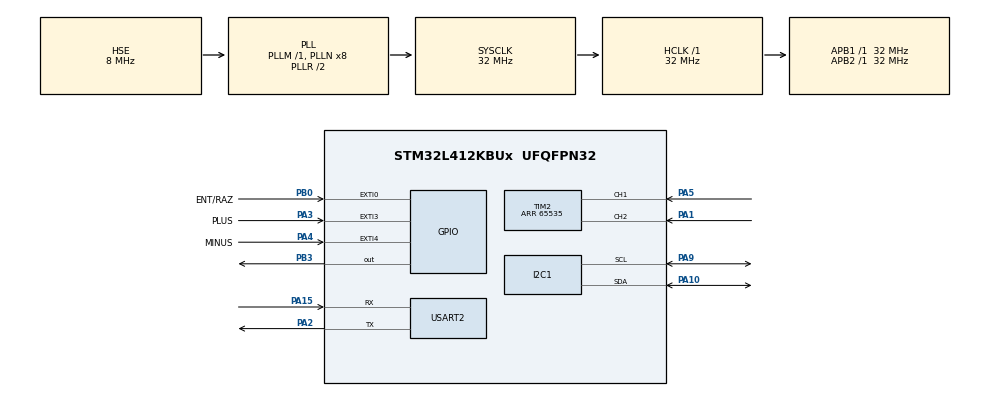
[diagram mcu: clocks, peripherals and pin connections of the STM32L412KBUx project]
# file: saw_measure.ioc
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Mcu.Family=STM32L4
Mcu.Name=STM32L412KBUx
Mcu.Package=UFQFPN32
NVIC.EXTI0_IRQn=true\:1\:0\:true\:false\:true\:true\:true
NVIC.EXTI3_IRQn=true\:3\:0\:true\:false\:true\:true\:true
NVIC.EXTI4_IRQn=true\:3\:0\:true\:false\:true\:true\:true
NVIC.PriorityGroup=NVIC_PRIORITYGROUP_4
NVIC.TIM2_IRQn=true\:0\:0\:false\:false\:true\:true\:true
PA0-CK_IN.Mode=HSE-External-Clock-Source-for-LittleOrca
PA0-CK_IN.Signal=RCC_CK_IN
PA1.Signal=S_TIM2_CH2
PA10.Mode=I2C
PA10.Signal=I2C1_SDA
PA13\ (JTMS/SWDIO).Mode=Serial_Wire
PA13\ (JTMS/SWDIO).Signal=SYS_JTMS-SWDIO
PA14\ (JTCK/SWCLK).Mode=Serial_Wire
PA14\ (JTCK/SWCLK).Signal=SYS_JTCK-SWCLK
PA15\ (JTDI).GPIO_ModeDefaultPP=GPIO_MODE_AF_PP
PA15\ (JTDI).GPIO_PuPd=GPIO_NOPULL
PA15\ (JTDI).GPIO_Speed=GPIO_SPEED_FREQ_VERY_HIGH
PA15\ (JTDI).Mode=Asynchronous
PA15\ (JTDI).Signal=USART2_RX
PA2.GPIO_ModeDefaultPP=GPIO_MODE_AF_PP
PA2.GPIO_PuPd=GPIO_NOPULL
PA2.GPIO_Speed=GPIO_SPEED_FREQ_VERY_HIGH
PA2.Mode=Asynchronous
PA2.Signal=USART2_TX
PA3.GPIO_Label=PLUS
PA3.GPIO_ModeDefaultEXTI=GPIO_MODE_IT_RISING
PA3.GPIO_PuPd=GPIO_NOPULL
PA3.Signal=GPXTI3
PA4.GPIO_Label=MINUS
PA4.GPIO_ModeDefaultEXTI=GPIO_MODE_IT_RISING
PA4.GPIO_PuPd=GPIO_NOPULL
PA4.Signal=GPXTI4
PA5.Signal=S_TIM2_CH1
PA9.Mode=I2C
PA9.Signal=I2C1_SCL
PB0.GPIO_Label=ENT/RAZ
PB0.GPIO_ModeDefaultEXTI=GPIO_MODE_IT_RISING
PB0.GPIO_PuPd=GPIO_NOPULL
PB0.Signal=GPXTI0
PB3\ (JTDO/TRACESWO).GPIO_ModeDefaultOutputPP=GPIO_MODE_OUTPUT_PP
PB3\ (JTDO/TRACESWO).GPIO_PuPd=GPIO_NOPULL
PB3\ (JTDO/TRACESWO).GPIO_Speed=GPIO_SPEED_FREQ_LOW
PB3\ (JTDO/TRACESWO).PinState=GPIO_PIN_RESET
PB3\ (JTDO/TRACESWO).Signal=GPIO_Output
PC14-OSC32_IN\ (PC14).Mode=LSE-External-Oscillator
PC14-OSC32_IN\ (PC14).Signal=RCC_OSC32_IN
PC15-OSC32_OUT\ (PC15).Mode=LSE-External-Oscillator
PC15-OSC32_OUT\ (PC15).Signal=RCC_OSC32_OUT
ProjectManager.HeapSize=0x200
ProjectManager.StackSize=0x400
ProjectManager.TargetToolchain=STM32CubeIDE
RCC.ADCFreq_Value=32000000
RCC.AHBFreq_Value=32000000
RCC.APB1Freq_Value=32000000
RCC.APB1TimFreq_Value=32000000
RCC.APB2Freq_Value=32000000
RCC.APB2TimFreq_Value=32000000
RCC.CortexFreq_Value=32000000
RCC.HCLKFreq_Value=32000000
RCC.HSE_VALUE=8000000
RCC.HSI48_VALUE=48000000
RCC.HSI_VALUE=16000000
RCC.MSI_VALUE=4000000
RCC.PLLSourceVirtual=RCC_PLLSOURCE_HSE
RCC.SYSCLKFreq_VALUE=32000000
RCC.SYSCLKSource=RCC_SYSCLKSOURCE_PLLCLK
RCC.USBFreq_Value=4000000
RCC.VCOOutputFreq_Value=64000000
SH.S_TIM2_CH1.0=TIM2_CH1,Encoder_Interface
SH.S_TIM2_CH2.0=TIM2_CH2,Encoder_Interface
TIM2.AutoReloadPreload=TIM_AUTORELOAD_PRELOAD_ENABLE
TIM2.EncoderMode=TIM_ENCODERMODE_TI12
TIM2.IC1Filter=10
TIM2.Period=65535
USART2.VirtualMode-Asynchronous=VM_ASYNC
board=NUCLEO-L412KB

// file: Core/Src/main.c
/* USER CODE BEGIN Header */
/**
  ******************************************************************************
  * @file           : main.c
  * @brief          : Main program body
  ******************************************************************************
  * @attention
  *
  * <h2><center>&copy; Copyright (c) 2020 STMicroelectronics.
  * All rights reserved.</center></h2>
  *
  * This software component is licensed by ST under BSD 3-Clause license,
  * the "License"; You may not use this file except in compliance with the
  * License. You may obtain a copy of the License at:
  *                        opensource.org/licenses/BSD-3-Clause
  *
  ******************************************************************************
  */
/* USER CODE END Header */
#include "main.h"

/* USER CODE BEGIN Includes */
#include "i2c-lcd.h"
#include "user_function.h"
#include <stdint.h>
/* USER CODE END Includes */

/* USER CODE BEGIN PD */

#define DEFAULT_TICKNESS 5U

uint8_t volatile valid_thickness = 0;
uint8_t volatile saw_thickness = DEFAULT_TICKNESS;
uint32_t volatile length = 0;

/* USER CODE END PD */

I2C_HandleTypeDef hi2c1;

TIM_HandleTypeDef htim2;

UART_HandleTypeDef huart2;

void SystemClock_Config(void);
static void MX_GPIO_Init(void);
static void MX_USART2_UART_Init(void);
static void MX_I2C1_Init(void);
static void MX_TIM2_Init(void);

int main(void)
{

  /* MCU Configuration--------------------------------------------------------*/

  /* Reset of all peripherals, Initializes the Flash interface and the Systick. */
  HAL_Init();

  /* USER CODE BEGIN Init */
  lcd_init();
  /* USER CODE END Init */

  /* Configure the system clock */
  SystemClock_Config();

  /* Initialize all configured peripherals */
  MX_GPIO_Init();
  MX_USART2_UART_Init();
  MX_I2C1_Init();
  MX_TIM2_Init();
  /* USER CODE BEGIN 2 */

  HAL_TIM_Encoder_Start_IT(&htim2, TIM_CHANNEL_ALL);

  /**
   * @brief First loop, ask user saw thickness as long as
   * 		user pressed ENTER/RAZ button
   */
  lcd_send_string("Ep lame :");
  display_saw_thickness(saw_thickness);

  while(!valid_thickness);

  display_measure(0 - saw_thickness);

  /* USER CODE END 2 */

  /* Infinite loop */
  while (1)
  {

  }
}

void SystemClock_Config(void)
{
  RCC_OscInitTypeDef RCC_OscInitStruct = {0};
  RCC_ClkInitTypeDef RCC_ClkInitStruct = {0};
  RCC_PeriphCLKInitTypeDef PeriphClkInit = {0};

  /** Configure the main internal regulator output voltage
  */
  if (HAL_PWREx_ControlVoltageScaling(PWR_REGULATOR_VOLTAGE_SCALE1) != HAL_OK)
  {
    Error_Handler();
  }
  /** Initializes the RCC Oscillators according to the specified parameters
  * in the RCC_OscInitTypeDef structure.
  */
  RCC_OscInitStruct.OscillatorType = RCC_OSCILLATORTYPE_HSE;
  RCC_OscInitStruct.HSEState = RCC_HSE_BYPASS;
  RCC_OscInitStruct.PLL.PLLState = RCC_PLL_ON;
  RCC_OscInitStruct.PLL.PLLSource = RCC_PLLSOURCE_HSE;
  RCC_OscInitStruct.PLL.PLLM = 1;
  RCC_OscInitStruct.PLL.PLLN = 8;
  RCC_OscInitStruct.PLL.PLLQ = RCC_PLLQ_DIV2;
  RCC_OscInitStruct.PLL.PLLR = RCC_PLLR_DIV2;
  if (HAL_RCC_OscConfig(&RCC_OscInitStruct) != HAL_OK)
  {
    Error_Handler();
  }
  /** Initializes the CPU, AHB and APB buses clocks
  */
  RCC_ClkInitStruct.ClockType = RCC_CLOCKTYPE_HCLK|RCC_CLOCKTYPE_SYSCLK
                              |RCC_CLOCKTYPE_PCLK1|RCC_CLOCKTYPE_PCLK2;
  RCC_ClkInitStruct.SYSCLKSource = RCC_SYSCLKSOURCE_PLLCLK;
  RCC_ClkInitStruct.AHBCLKDivider = RCC_SYSCLK_DIV1;
  RCC_ClkInitStruct.APB1CLKDivider = RCC_HCLK_DIV1;
  RCC_ClkInitStruct.APB2CLKDivider = RCC_HCLK_DIV1;

  if (HAL_RCC_ClockConfig(&RCC_ClkInitStruct, FLASH_LATENCY_1) != HAL_OK)
  {
    Error_Handler();
  }
  PeriphClkInit.PeriphClockSelection = RCC_PERIPHCLK_USART2|RCC_PERIPHCLK_I2C1;
  PeriphClkInit.Usart2ClockSelection = RCC_USART2CLKSOURCE_PCLK1;
  PeriphClkInit.I2c1ClockSelection = RCC_I2C1CLKSOURCE_PCLK1;
  if (HAL_RCCEx_PeriphCLKConfig(&PeriphClkInit) != HAL_OK)
  {
    Error_Handler();
  }
}

static void MX_I2C1_Init(void)
{

  hi2c1.Instance = I2C1;
  hi2c1.Init.Timing = 0x00000E14;
  hi2c1.Init.OwnAddress1 = 0;
  hi2c1.Init.AddressingMode = I2C_ADDRESSINGMODE_7BIT;
  hi2c1.Init.DualAddressMode = I2C_DUALADDRESS_DISABLE;
  hi2c1.Init.OwnAddress2 = 0;
  hi2c1.Init.OwnAddress2Masks = I2C_OA2_NOMASK;
  hi2c1.Init.GeneralCallMode = I2C_GENERALCALL_DISABLE;
  hi2c1.Init.NoStretchMode = I2C_NOSTRETCH_DISABLE;
  if (HAL_I2C_Init(&hi2c1) != HAL_OK)
  {
    Error_Handler();
  }
  /** Configure Analogue filter
  */
  if (HAL_I2CEx_ConfigAnalogFilter(&hi2c1, I2C_ANALOGFILTER_ENABLE) != HAL_OK)
  {
    Error_Handler();
  }
  /** Configure Digital filter
  */
  if (HAL_I2CEx_ConfigDigitalFilter(&hi2c1, 0) != HAL_OK)
  {
    Error_Handler();
  }

}

static void MX_TIM2_Init(void)
{

  TIM_Encoder_InitTypeDef sConfig = {0};
  TIM_MasterConfigTypeDef sMasterConfig = {0};

  htim2.Instance = TIM2;
  htim2.Init.Prescaler = 0;
  htim2.Init.CounterMode = TIM_COUNTERMODE_UP;
  htim2.Init.Period = 65535;
  htim2.Init.ClockDivision = TIM_CLOCKDIVISION_DIV1;
  htim2.Init.AutoReloadPreload = TIM_AUTORELOAD_PRELOAD_ENABLE;
  sConfig.EncoderMode = TIM_ENCODERMODE_TI12;
  sConfig.IC1Polarity = TIM_ICPOLARITY_RISING;
  sConfig.IC1Selection = TIM_ICSELECTION_DIRECTTI;
  sConfig.IC1Prescaler = TIM_ICPSC_DIV1;
  sConfig.IC1Filter = 10;
  sConfig.IC2Polarity = TIM_ICPOLARITY_RISING;
  sConfig.IC2Selection = TIM_ICSELECTION_DIRECTTI;
  sConfig.IC2Prescaler = TIM_ICPSC_DIV1;
  sConfig.IC2Filter = 0;
  if (HAL_TIM_Encoder_Init(&htim2, &sConfig) != HAL_OK)
  {
    Error_Handler();
  }
  sMasterConfig.MasterOutputTrigger = TIM_TRGO_RESET;
  sMasterConfig.MasterSlaveMode = TIM_MASTERSLAVEMODE_DISABLE;
  if (HAL_TIMEx_MasterConfigSynchronization(&htim2, &sMasterConfig) != HAL_OK)
  {
    Error_Handler();
  }

}

static void MX_USART2_UART_Init(void)
{

  huart2.Instance = USART2;
  huart2.Init.BaudRate = 115200;
  huart2.Init.WordLength = UART_WORDLENGTH_8B;
  huart2.Init.StopBits = UART_STOPBITS_1;
  huart2.Init.Parity = UART_PARITY_NONE;
  huart2.Init.Mode = UART_MODE_TX_RX;
  huart2.Init.HwFlowCtl = UART_HWCONTROL_NONE;
  huart2.Init.OverSampling = UART_OVERSAMPLING_16;
  huart2.Init.OneBitSampling = UART_ONE_BIT_SAMPLE_DISABLE;
  huart2.AdvancedInit.AdvFeatureInit = UART_ADVFEATURE_NO_INIT;
  if (HAL_UART_Init(&huart2) != HAL_OK)
  {
    Error_Handler();
  }

}

static void MX_GPIO_Init(void)
{
  GPIO_InitTypeDef GPIO_InitStruct = {0};

  /* GPIO Ports Clock Enable */
  __HAL_RCC_GPIOC_CLK_ENABLE();
  __HAL_RCC_GPIOA_CLK_ENABLE();
  __HAL_RCC_GPIOB_CLK_ENABLE();

  /*Configure GPIO pin Output Level */
  HAL_GPIO_WritePin(GPIOB, GPIO_PIN_3, GPIO_PIN_RESET);

  /*Configure GPIO pins : PLUS_Pin MINUS_Pin */
  GPIO_InitStruct.Pin = PLUS_Pin|MINUS_Pin;
  GPIO_InitStruct.Mode = GPIO_MODE_IT_RISING;
  GPIO_InitStruct.Pull = GPIO_NOPULL;
  HAL_GPIO_Init(GPIOA, &GPIO_InitStruct);

  /*Configure GPIO pin : ENT_RAZ_Pin */
  GPIO_InitStruct.Pin = ENT_RAZ_Pin;
  GPIO_InitStruct.Mode = GPIO_MODE_IT_RISING;
  GPIO_InitStruct.Pull = GPIO_NOPULL;
  HAL_GPIO_Init(ENT_RAZ_GPIO_Port, &GPIO_InitStruct);

  /*Configure GPIO pin : PB3 */
  GPIO_InitStruct.Pin = GPIO_PIN_3;
  GPIO_InitStruct.Mode = GPIO_MODE_OUTPUT_PP;
  GPIO_InitStruct.Pull = GPIO_NOPULL;
  GPIO_InitStruct.Speed = GPIO_SPEED_FREQ_LOW;
  HAL_GPIO_Init(GPIOB, &GPIO_InitStruct);

  /* EXTI interrupt init*/
  HAL_NVIC_SetPriority(EXTI0_IRQn, 1, 0);
  HAL_NVIC_EnableIRQ(EXTI0_IRQn);

  HAL_NVIC_SetPriority(EXTI3_IRQn, 3, 0);
  HAL_NVIC_EnableIRQ(EXTI3_IRQn);

  HAL_NVIC_SetPriority(EXTI4_IRQn, 3, 0);
  HAL_NVIC_EnableIRQ(EXTI4_IRQn);

}

void Error_Handler(void)
{
}

/************************ (C) COPYRIGHT STMicroelectronics *****END OF FILE****/
